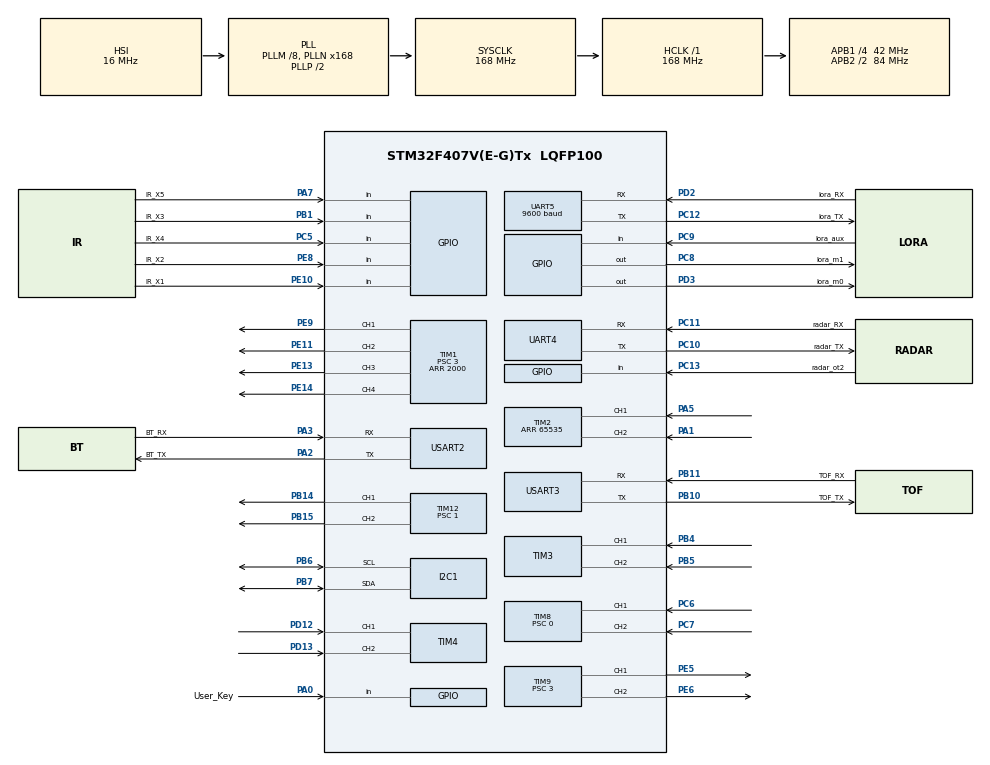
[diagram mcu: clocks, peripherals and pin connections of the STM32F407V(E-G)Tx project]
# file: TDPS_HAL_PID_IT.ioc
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I2C1.I2C_Mode=I2C_Fast
Mcu.Family=STM32F4
Mcu.Name=STM32F407V(E-G)Tx
Mcu.Package=LQFP100
NVIC.PriorityGroup=NVIC_PRIORITYGROUP_4
NVIC.TIM6_DAC_IRQn=true\:1\:0\:true\:false\:true\:true\:true\:true
PA0-WKUP.GPIO_Label=User_Key
PA0-WKUP.Signal=GPIO_Input
PA1.Signal=S_TIM2_CH2
PA13.Mode=Serial_Wire
PA13.Signal=SYS_JTMS-SWDIO
PA14.Mode=Serial_Wire
PA14.Signal=SYS_JTCK-SWCLK
PA2.GPIO_Label=BT_TX
PA2.Mode=Asynchronous
PA2.Signal=USART2_TX
PA3.GPIO_Label=BT_RX
PA3.Mode=Asynchronous
PA3.Signal=USART2_RX
PA5.Signal=S_TIM2_CH1_ETR
PA7.GPIO_Label=IR_X5
PA7.Signal=GPIO_Input
PB1.GPIO_Label=IR_X3
PB1.Signal=GPIO_Input
PB10.GPIO_Label=TOF_TX
PB10.Mode=Asynchronous
PB10.Signal=USART3_TX
PB11.GPIO_Label=TOF_RX
PB11.Mode=Asynchronous
PB11.Signal=USART3_RX
PB14.Signal=S_TIM12_CH1
PB15.Signal=S_TIM12_CH2
PB4.Signal=S_TIM3_CH1
PB5.Signal=S_TIM3_CH2
PB6.Mode=I2C
PB6.Signal=I2C1_SCL
PB7.Mode=I2C
PB7.Signal=I2C1_SDA
PC10.GPIO_Label=radar_TX
PC10.Mode=Asynchronous
PC10.Signal=UART4_TX
PC11.GPIO_Label=radar_RX
PC11.Mode=Asynchronous
PC11.Signal=UART4_RX
PC12.GPIO_Label=lora_TX
PC12.Mode=Asynchronous
PC12.Signal=UART5_TX
PC13-ANTI_TAMP.GPIO_Label=radar_ot2
PC13-ANTI_TAMP.Signal=GPIO_Input
PC14-OSC32_IN.Mode=LSE-External-Oscillator
PC14-OSC32_IN.Signal=RCC_OSC32_IN
PC15-OSC32_OUT.Mode=LSE-External-Oscillator
PC15-OSC32_OUT.Signal=RCC_OSC32_OUT
PC5.GPIO_Label=IR_X4
PC5.Signal=GPIO_Input
PC6.Signal=S_TIM8_CH1
PC7.Signal=S_TIM8_CH2
PC8.GPIO_Label=lora_m1
PC8.GPIO_Speed=GPIO_SPEED_FREQ_LOW
PC8.PinState=GPIO_PIN_SET
PC8.Signal=GPIO_Output
PC9.GPIO_Label=lora_aux
PC9.Signal=GPIO_Input
PD12.Signal=S_TIM4_CH1
PD13.Signal=S_TIM4_CH2
PD2.GPIO_Label=lora_RX
PD2.Mode=Asynchronous
PD2.Signal=UART5_RX
PD3.GPIO_Label=lora_m0
PD3.GPIO_Speed=GPIO_SPEED_FREQ_LOW
PD3.PinState=GPIO_PIN_SET
PD3.Signal=GPIO_Output
PE10.GPIO_Label=IR_X1
PE10.Signal=GPIO_Input
PE11.Signal=S_TIM1_CH2
PE13.Signal=S_TIM1_CH3
PE14.Signal=S_TIM1_CH4
PE5.Signal=S_TIM9_CH1
PE6.Signal=S_TIM9_CH2
PE8.GPIO_Label=IR_X2
PE8.Signal=GPIO_Input
PE9.Signal=S_TIM1_CH1
PH0-OSC_IN.Mode=HSE-External-Oscillator
PH0-OSC_IN.Signal=RCC_OSC_IN
PH1-OSC_OUT.Mode=HSE-External-Oscillator
PH1-OSC_OUT.Signal=RCC_OSC_OUT
ProjectManager.HeapSize=0x200
ProjectManager.StackSize=0x400
ProjectManager.TargetToolchain=MDK-ARM V5.32
RCC.48MHZClocksFreq_Value=84000000
RCC.AHBFreq_Value=168000000
RCC.APB1CLKDivider=RCC_HCLK_DIV4
RCC.APB1Freq_Value=42000000
RCC.APB1TimFreq_Value=84000000
RCC.APB2CLKDivider=RCC_HCLK_DIV2
RCC.APB2Freq_Value=84000000
RCC.APB2TimFreq_Value=168000000
RCC.CortexFreq_Value=168000000
RCC.HCLKFreq_Value=168000000
RCC.HSE_VALUE=8000000
RCC.HSI_VALUE=16000000
RCC.PLLM=8
RCC.PLLN=168
RCC.SYSCLKFreq_VALUE=168000000
RCC.SYSCLKSource=RCC_SYSCLKSOURCE_PLLCLK
RCC.VCOOutputFreq_Value=336000000
SH.S_TIM12_CH1.0=TIM12_CH1,PWM Generation1 CH1
SH.S_TIM12_CH2.0=TIM12_CH2,PWM Generation2 CH2
SH.S_TIM1_CH1.0=TIM1_CH1,PWM Generation1 CH1
SH.S_TIM1_CH2.0=TIM1_CH2,PWM Generation2 CH2
SH.S_TIM1_CH3.0=TIM1_CH3,PWM Generation3 CH3
SH.S_TIM1_CH4.0=TIM1_CH4,PWM Generation4 CH4
SH.S_TIM2_CH1_ETR.0=TIM2_CH1,Encoder_Interface
SH.S_TIM2_CH2.0=TIM2_CH2,Encoder_Interface
SH.S_TIM3_CH1.0=TIM3_CH1,Encoder_Interface
SH.S_TIM3_CH2.0=TIM3_CH2,Encoder_Interface
SH.S_TIM4_CH1.0=TIM4_CH1,Encoder_Interface
SH.S_TIM4_CH2.0=TIM4_CH2,Encoder_Interface
SH.S_TIM8_CH1.0=TIM8_CH1,Encoder_Interface
SH.S_TIM8_CH2.0=TIM8_CH2,Encoder_Interface
SH.S_TIM9_CH1.0=TIM9_CH1,PWM Generation1 CH1
SH.S_TIM9_CH2.0=TIM9_CH2,PWM Generation2 CH2
TIM1.Channel-PWM\ Generation1\ CH1=TIM_CHANNEL_1
TIM1.Channel-PWM\ Generation2\ CH2=TIM_CHANNEL_2
TIM1.Channel-PWM\ Generation3\ CH3=TIM_CHANNEL_3
TIM1.Channel-PWM\ Generation4\ CH4=TIM_CHANNEL_4
TIM1.Period=2000
TIM1.Prescaler=3
TIM12.Channel-PWM\ Generation1\ CH1=TIM_CHANNEL_1
TIM12.Channel-PWM\ Generation2\ CH2=TIM_CHANNEL_2
TIM12.Period=2000
TIM12.Prescaler=1
TIM2.EncoderMode=TIM_ENCODERMODE_TI12
TIM2.IC2Filter=10
TIM2.Period=65535
TIM3.EncoderMode=TIM_ENCODERMODE_TI12
TIM3.IC2Filter=10
TIM4.EncoderMode=TIM_ENCODERMODE_TI12
TIM4.IC2Filter=10
TIM6.AutoReloadPreload=TIM_AUTORELOAD_PRELOAD_ENABLE
TIM6.Period=100-1
TIM6.Prescaler=8400-1
TIM8.EncoderMode=TIM_ENCODERMODE_TI12
TIM8.IC2Filter=10
TIM8.Prescaler=0
TIM9.Channel-PWM\ Generation1\ CH1=TIM_CHANNEL_1
TIM9.Channel-PWM\ Generation2\ CH2=TIM_CHANNEL_2
TIM9.Period=2000
TIM9.Prescaler=3
UART4.VirtualMode=Asynchronous
UART5.BaudRate=9600
UART5.VirtualMode=Asynchronous
USART2.VirtualMode=VM_ASYNC
USART3.VirtualMode=VM_ASYNC
VP_RTC_VS_RTC_Activate.Mode=RTC_Enabled
VP_RTC_VS_RTC_Calendar.Mode=RTC_Calendar
VP_TIM12_VS_ClockSourceINT.Mode=Internal
VP_TIM1_VS_ClockSourceINT.Mode=Internal
VP_TIM6_VS_ClockSourceINT.Mode=Enable_Timer
VP_TIM9_VS_ClockSourceINT.Mode=Internal
board=custom

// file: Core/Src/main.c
/* USER CODE BEGIN Header */
/**
  ******************************************************************************
  * @file           : main.c
  * @brief          : Main program body
  ******************************************************************************
  * @attention
  *
  * Copyright (c) 2026 STMicroelectronics.
  * All rights reserved.
  *
  * This software is licensed under terms that can be found in the LICENSE file
  * in the root directory of this software component.
  * If no LICENSE file comes with this software, it is provided AS-IS.
  *
  ******************************************************************************
  */
/* USER CODE END Header */
#include "main.h"
#include "i2c.h"
#include "rtc.h"
#include "tim.h"
#include "usart.h"
#include "gpio.h"

/* USER CODE BEGIN Includes */
#include "motor.h"
#include "tracking.h"
#include "lora.h"
#include "oled.h"
#include "ld2410s.h"
/* USER CODE END Includes */

void SystemClock_Config(void);

int main(void)
{

  /* MCU Configuration--------------------------------------------------------*/

  /* Reset of all peripherals, Initializes the Flash interface and the Systick. */
  HAL_Init();

  /* Configure the system clock */
  SystemClock_Config();

  /* Initialize all configured peripherals */
  MX_GPIO_Init();
  MX_UART4_Init();
  MX_UART5_Init();
  MX_USART2_UART_Init();
  MX_I2C1_Init();
  MX_RTC_Init();
  MX_TIM1_Init();
  MX_TIM2_Init();
  MX_TIM3_Init();
  MX_TIM4_Init();
  MX_TIM8_Init();
  MX_TIM9_Init();
  MX_TIM12_Init();
  MX_USART3_UART_Init();
  MX_TIM6_Init();
  /* USER CODE BEGIN 2 */
	App_Motor_Init();
	Tracking_Init();
	LoRa_Init();
	TOF_Init();
	OLED_Init();
	LD2410S_Init();
  /* USER CODE END 2 */

  /* Infinite loop */
  while (1)
  {

    /* USER CODE BEGIN 3 */
		Tracking_Pro_Run();
		//TOF_CheckAndSend();
		//LD2410S_SoftRestart();
		//HAL_Delay(2000);
  }
  /* USER CODE END 3 */
}

void SystemClock_Config(void)
{
  RCC_OscInitTypeDef RCC_OscInitStruct = {0};
  RCC_ClkInitTypeDef RCC_ClkInitStruct = {0};

  /** Configure the main internal regulator output voltage
  */
  __HAL_RCC_PWR_CLK_ENABLE();
  __HAL_PWR_VOLTAGESCALING_CONFIG(PWR_REGULATOR_VOLTAGE_SCALE1);

  /** Initializes the RCC Oscillators according to the specified parameters
  * in the RCC_OscInitTypeDef structure.
  */
  RCC_OscInitStruct.OscillatorType = RCC_OSCILLATORTYPE_HSI|RCC_OSCILLATORTYPE_LSI;
  RCC_OscInitStruct.HSIState = RCC_HSI_ON;
  RCC_OscInitStruct.HSICalibrationValue = RCC_HSICALIBRATION_DEFAULT;
  RCC_OscInitStruct.LSIState = RCC_LSI_ON;
  RCC_OscInitStruct.PLL.PLLState = RCC_PLL_ON;
  RCC_OscInitStruct.PLL.PLLSource = RCC_PLLSOURCE_HSI;
  RCC_OscInitStruct.PLL.PLLM = 8;
  RCC_OscInitStruct.PLL.PLLN = 168;
  RCC_OscInitStruct.PLL.PLLP = RCC_PLLP_DIV2;
  RCC_OscInitStruct.PLL.PLLQ = 4;
  if (HAL_RCC_OscConfig(&RCC_OscInitStruct) != HAL_OK)
  {
    Error_Handler();
  }

  /** Initializes the CPU, AHB and APB buses clocks
  */
  RCC_ClkInitStruct.ClockType = RCC_CLOCKTYPE_HCLK|RCC_CLOCKTYPE_SYSCLK
                              |RCC_CLOCKTYPE_PCLK1|RCC_CLOCKTYPE_PCLK2;
  RCC_ClkInitStruct.SYSCLKSource = RCC_SYSCLKSOURCE_PLLCLK;
  RCC_ClkInitStruct.AHBCLKDivider = RCC_SYSCLK_DIV1;
  RCC_ClkInitStruct.APB1CLKDivider = RCC_HCLK_DIV4;
  RCC_ClkInitStruct.APB2CLKDivider = RCC_HCLK_DIV2;

  if (HAL_RCC_ClockConfig(&RCC_ClkInitStruct, FLASH_LATENCY_5) != HAL_OK)
  {
    Error_Handler();
  }
}

void Error_Handler(void)
{
  /* USER CODE BEGIN Error_Handler_Debug */
  /* User can add his own implementation to report the HAL error return state */
  __disable_irq();
	uint8_t msg[]="STM32 Error";
  while (1)
  {
		LoRa_Send_FixedPoint(0x0003,0x1E,msg,sizeof(msg)-1);
  }
  /* USER CODE END Error_Handler_Debug */
}
